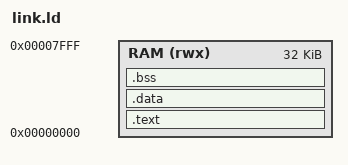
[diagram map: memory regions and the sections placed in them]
/* Linker script for PicoRV32 RISC-V SoC with 32 KB Block RAM */

MEMORY
{
    RAM (rwx) : ORIGIN = 0x00000000, LENGTH = 32K
}

ENTRY(_start)

SECTIONS
{
    .text : {
        . = ALIGN(4);
        *(.text.start)
        *(.text*)
        *(.rodata*)
        . = ALIGN(4);
    } > RAM

    .data : {
        . = ALIGN(4);
        *(.data*)
        *(.sdata*)
        . = ALIGN(4);
    } > RAM

    .bss : {
        . = ALIGN(4);
        __bss_start = .;
        *(.bss*)
        *(.sbss*)
        *(COMMON)
        . = ALIGN(4);
        __bss_end = .;
    } > RAM

    /* Stack pointer starts from top of RAM */
    __stack_top = 0x00007FF0;
}
